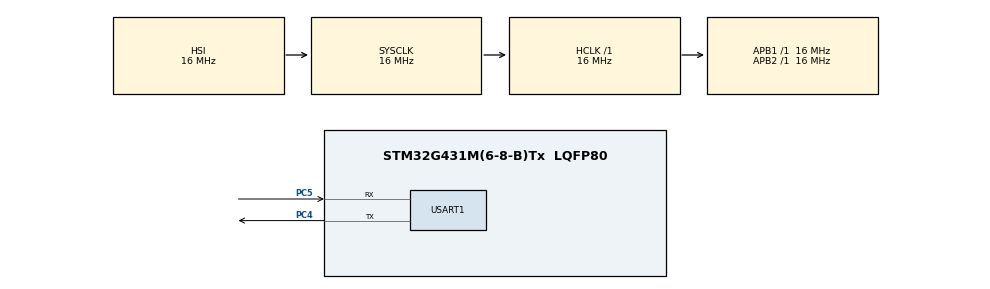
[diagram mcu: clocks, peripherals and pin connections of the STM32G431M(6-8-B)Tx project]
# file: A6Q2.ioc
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Dma.Request0=USART1_RX
Dma.USART1_RX.0.Direction=DMA_PERIPH_TO_MEMORY
Dma.USART1_RX.0.EventEnable=DISABLE
Dma.USART1_RX.0.Instance=DMA1_Channel1
Dma.USART1_RX.0.MemDataAlignment=DMA_MDATAALIGN_BYTE
Dma.USART1_RX.0.MemInc=DMA_MINC_ENABLE
Dma.USART1_RX.0.Mode=DMA_CIRCULAR
Dma.USART1_RX.0.PeriphDataAlignment=DMA_PDATAALIGN_BYTE
Dma.USART1_RX.0.PeriphInc=DMA_PINC_DISABLE
Dma.USART1_RX.0.Polarity=HAL_DMAMUX_REQ_GEN_RISING
Dma.USART1_RX.0.Priority=DMA_PRIORITY_LOW
Dma.USART1_RX.0.RequestNumber=1
Dma.USART1_RX.0.SignalID=NONE
Dma.USART1_RX.0.SyncEnable=DISABLE
Dma.USART1_RX.0.SyncPolarity=HAL_DMAMUX_SYNC_NO_EVENT
Dma.USART1_RX.0.SyncRequestNumber=1
Dma.USART1_RX.0.SyncSignalID=NONE
Mcu.Family=STM32G4
Mcu.Name=STM32G431M(6-8-B)Tx
Mcu.Package=LQFP80
NVIC.DMA1_Channel1_IRQn=true\:0\:0\:false\:false\:true\:false\:true\:true
NVIC.PriorityGroup=NVIC_PRIORITYGROUP_4
PA13.Mode=Serial_Wire
PA13.Signal=SYS_JTMS-SWDIO
PA14.Mode=Serial_Wire
PA14.Signal=SYS_JTCK-SWCLK
PC4.Mode=Asynchronous
PC4.Signal=USART1_TX
PC5.Mode=Asynchronous
PC5.Signal=USART1_RX
ProjectManager.HeapSize=0x200
ProjectManager.StackSize=0x400
ProjectManager.TargetToolchain=STM32CubeIDE
RCC.AHBFreq_Value=16000000
RCC.APB1Freq_Value=16000000
RCC.APB1TimFreq_Value=16000000
RCC.APB2Freq_Value=16000000
RCC.APB2TimFreq_Value=16000000
RCC.CortexFreq_Value=16000000
RCC.EXTERNAL_CLOCK_VALUE=12288000
RCC.HCLKFreq_Value=16000000
RCC.HSE_VALUE=8000000
RCC.HSI48_VALUE=48000000
RCC.HSI_VALUE=16000000
RCC.LSE_VALUE=32768
RCC.SYSCLKFreq_VALUE=16000000
RCC.USBFreq_Value=64000000
RCC.VCOOutputFreq_Value=128000000
USART1.VirtualMode-Asynchronous=VM_ASYNC
VP_SYS_VS_DBSignals.Mode=DisableDeadBatterySignals
board=custom

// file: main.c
/* USER CODE BEGIN Header */
/**
  ******************************************************************************
  * @file           : main.c
  * @brief          : Main program body
  ******************************************************************************
  * @attention
  *
  * Copyright (c) 2024 STMicroelectronics.
  * All rights reserved.
  *
  * This software is licensed under terms that can be found in the LICENSE file
  * in the root directory of this software component.
  * If no LICENSE file comes with this software, it is provided AS-IS.
  *
  ******************************************************************************
  */
/* USER CODE END Header */
#include "main.h"

UART_HandleTypeDef huart1;
DMA_HandleTypeDef hdma_usart1_rx;

/* USER CODE BEGIN PV */
uint8_t rxdata[10];
/* USER CODE END PV */

void SystemClock_Config(void);
static void MX_GPIO_Init(void);
static void MX_DMA_Init(void);
static void MX_USART1_UART_Init(void);

/* USER CODE BEGIN 0 */
//void HAL_UART_RxCpltCallback(UART_HandleTypeDef *huart)
//{
// /* Prevent unused argument(s) compilation warning */
// UNUSED(huart);
//         HAL_UART_Transmit(&huart1, rxdata, sizeof(rxdata), 100);
// 	 	  HAL_UART_Transmit(&huart1, (uint8_t*)"\r\n", 2, 100);
// 	 	  HAL_Delay(750);
//
// /* NOTE : This function should not be modified, when the callback is needed,
//           the HAL_UART_RxCpltCallback can be implemented in the user file.
//  */
//}
/* USER CODE END 0 */

int main(void)
{

  /* MCU Configuration--------------------------------------------------------*/

  /* Reset of all peripherals, Initializes the Flash interface and the Systick. */
  HAL_Init();

  /* Configure the system clock */
  SystemClock_Config();

  /* Initialize all configured peripherals */
  MX_GPIO_Init();
  MX_DMA_Init();
  MX_USART1_UART_Init();
  /* USER CODE BEGIN 2 */

  HAL_UART_Receive_DMA(&huart1, rxdata, sizeof(rxdata));
  /* USER CODE END 2 */

  /* Infinite loop */
  /* USER CODE BEGIN WHILE */
  while (1)
  {
	  HAL_UART_Transmit(&huart1, rxdata, sizeof(rxdata), 100);

	          // Optionally send a newline for formatting the output on the console
	          HAL_UART_Transmit(&huart1, (uint8_t*)"\r\n", 2, 100);

	          // Add a small delay to avoid overwhelming the UART interface
	          HAL_Delay(100);

    /* USER CODE END WHILE */

  }
}

void SystemClock_Config(void)
{
  RCC_OscInitTypeDef RCC_OscInitStruct = {0};
  RCC_ClkInitTypeDef RCC_ClkInitStruct = {0};

  /** Configure the main internal regulator output voltage
  */
  HAL_PWREx_ControlVoltageScaling(PWR_REGULATOR_VOLTAGE_SCALE1);

  /** Initializes the RCC Oscillators according to the specified parameters
  * in the RCC_OscInitTypeDef structure.
  */
  RCC_OscInitStruct.OscillatorType = RCC_OSCILLATORTYPE_HSI;
  RCC_OscInitStruct.HSIState = RCC_HSI_ON;
  RCC_OscInitStruct.HSICalibrationValue = RCC_HSICALIBRATION_DEFAULT;
  RCC_OscInitStruct.PLL.PLLState = RCC_PLL_NONE;
  if (HAL_RCC_OscConfig(&RCC_OscInitStruct) != HAL_OK)
  {
    Error_Handler();
  }

  /** Initializes the CPU, AHB and APB buses clocks
  */
  RCC_ClkInitStruct.ClockType = RCC_CLOCKTYPE_HCLK|RCC_CLOCKTYPE_SYSCLK
                              |RCC_CLOCKTYPE_PCLK1|RCC_CLOCKTYPE_PCLK2;
  RCC_ClkInitStruct.SYSCLKSource = RCC_SYSCLKSOURCE_HSI;
  RCC_ClkInitStruct.AHBCLKDivider = RCC_SYSCLK_DIV1;
  RCC_ClkInitStruct.APB1CLKDivider = RCC_HCLK_DIV1;
  RCC_ClkInitStruct.APB2CLKDivider = RCC_HCLK_DIV1;

  if (HAL_RCC_ClockConfig(&RCC_ClkInitStruct, FLASH_LATENCY_0) != HAL_OK)
  {
    Error_Handler();
  }
}

static void MX_USART1_UART_Init(void)
{

  huart1.Instance = USART1;
  huart1.Init.BaudRate = 115200;
  huart1.Init.WordLength = UART_WORDLENGTH_8B;
  huart1.Init.StopBits = UART_STOPBITS_1;
  huart1.Init.Parity = UART_PARITY_NONE;
  huart1.Init.Mode = UART_MODE_TX_RX;
  huart1.Init.HwFlowCtl = UART_HWCONTROL_NONE;
  huart1.Init.OverSampling = UART_OVERSAMPLING_16;
  huart1.Init.OneBitSampling = UART_ONE_BIT_SAMPLE_DISABLE;
  huart1.Init.ClockPrescaler = UART_PRESCALER_DIV1;
  huart1.AdvancedInit.AdvFeatureInit = UART_ADVFEATURE_NO_INIT;
  if (HAL_UART_Init(&huart1) != HAL_OK)
  {
    Error_Handler();
  }
  if (HAL_UARTEx_SetTxFifoThreshold(&huart1, UART_TXFIFO_THRESHOLD_1_8) != HAL_OK)
  {
    Error_Handler();
  }
  if (HAL_UARTEx_SetRxFifoThreshold(&huart1, UART_RXFIFO_THRESHOLD_1_8) != HAL_OK)
  {
    Error_Handler();
  }
  if (HAL_UARTEx_DisableFifoMode(&huart1) != HAL_OK)
  {
    Error_Handler();
  }

}

static void MX_DMA_Init(void)
{

  /* DMA controller clock enable */
  __HAL_RCC_DMAMUX1_CLK_ENABLE();
  __HAL_RCC_DMA1_CLK_ENABLE();

  /* DMA interrupt init */
  /* DMA1_Channel1_IRQn interrupt configuration */
  HAL_NVIC_SetPriority(DMA1_Channel1_IRQn, 0, 0);
  HAL_NVIC_EnableIRQ(DMA1_Channel1_IRQn);

}

static void MX_GPIO_Init(void)
{

  /* GPIO Ports Clock Enable */
  __HAL_RCC_GPIOC_CLK_ENABLE();
  __HAL_RCC_GPIOA_CLK_ENABLE();

}

void Error_Handler(void)
{
  __disable_irq();
  while (1)
  {
  }
}
